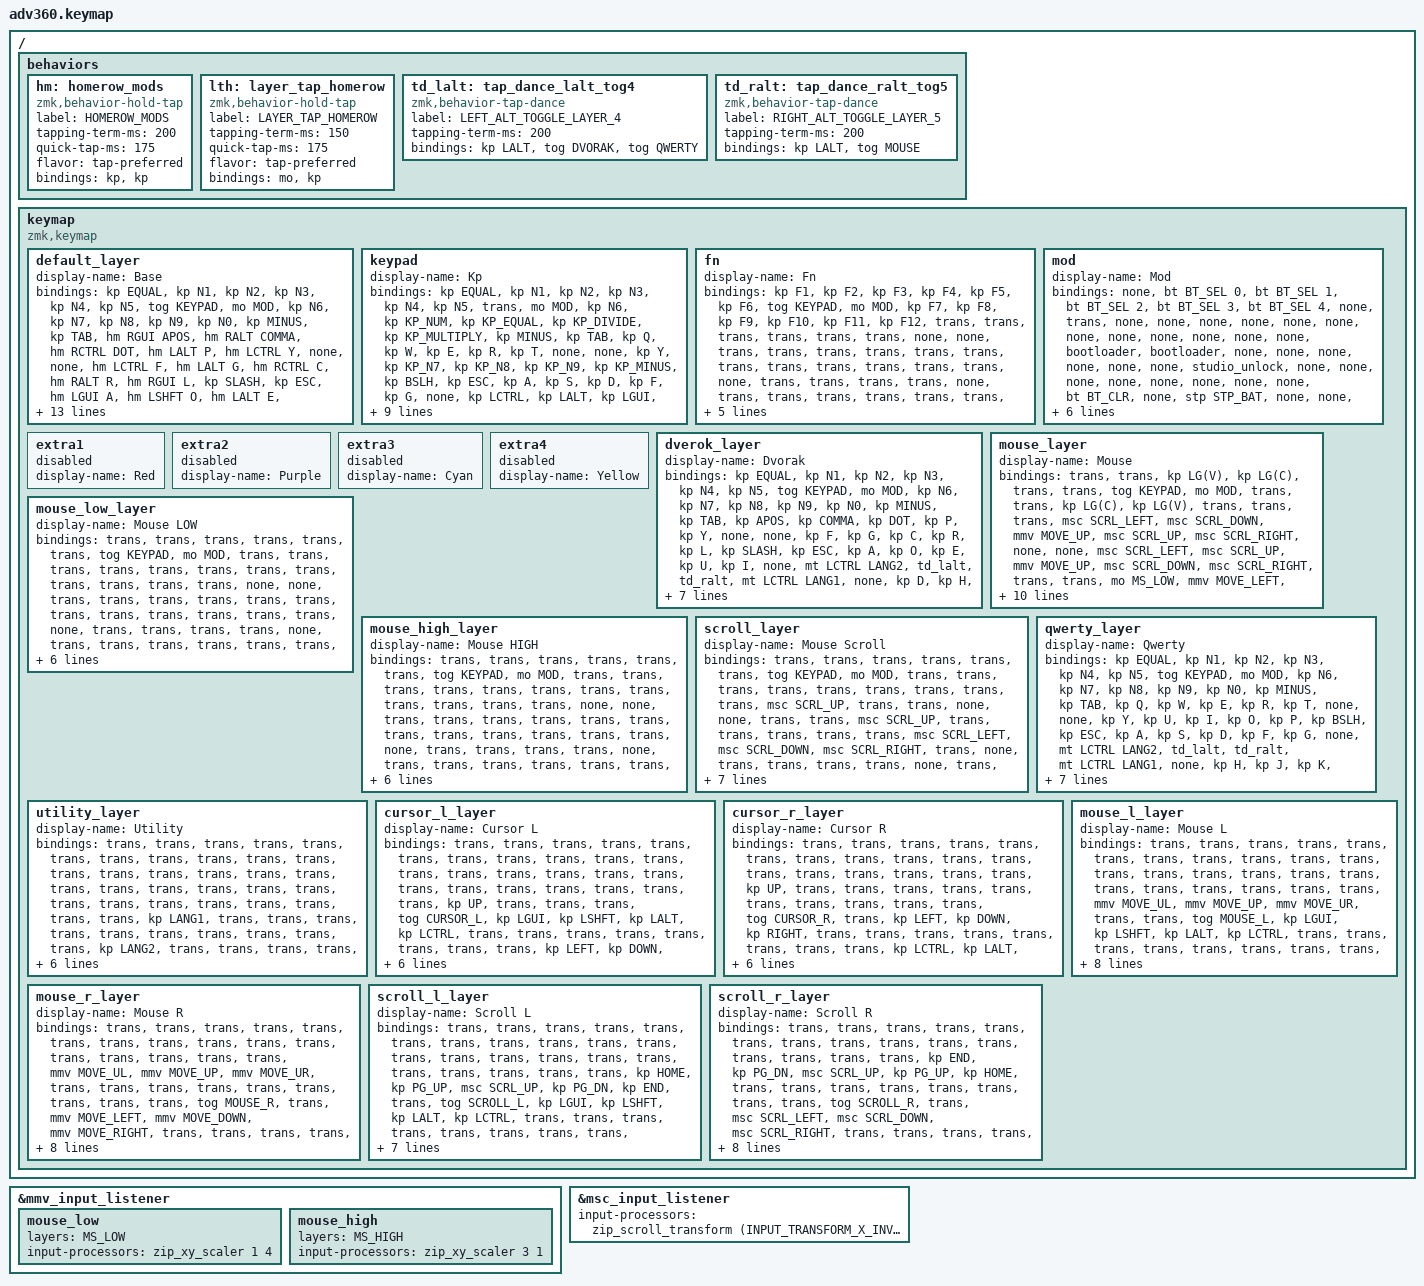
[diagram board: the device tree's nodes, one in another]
#include <behaviors.dtsi>
#include <dt-bindings/zmk/keys.h>
#include <dt-bindings/zmk/bt.h>
#include <dt-bindings/zmk/rgb.h>
#include <dt-bindings/zmk/stp.h>
#include <dt-bindings/zmk/backlight.h>

#define ZMK_POINTING_DEFAULT_MOVE_VAL 600  /* 600 */
#define ZMK_POINTING_DEFAULT_SCRL_VAL 20   /*  10 */
#include <dt-bindings/zmk/pointing.h>
/* Diagonal mouse moves (X and Y are encoded in separate bits) */
#define MOVE_UL (MOVE_UP | MOVE_LEFT)
#define MOVE_UR (MOVE_UP | MOVE_RIGHT)
#define MOVE_DL (MOVE_DOWN | MOVE_LEFT)
#define MOVE_DR (MOVE_DOWN | MOVE_RIGHT)
#include <input/processors.dtsi>
#include <dt-bindings/zmk/input_transform.h>

/* Layer indices (keep in sync with the order of layers in keymap) */
#define BASE    0
#define KEYPAD  1
#define FN      2
#define MOD     3
#define DVORAK  4
#define MOUSE   5
#define MS_LOW  6
#define MS_HIGH 7
#define SCROLL  8
#define QWERTY  9
#define UTIL    10
#define CURSOR_L 11
#define CURSOR_R 12
#define MOUSE_L 13
#define MOUSE_R 14
#define SCROLL_L 15
#define SCROLL_R 16

/ {
    behaviors {
      #include "macros.dtsi"
      #include "version.dtsi"

      hm: homerow_mods {
          compatible = "zmk,behavior-hold-tap";
          label = "HOMEROW_MODS";
          #binding-cells = <2>;
          tapping-term-ms = <200>;
          quick-tap-ms = <175>;
          flavor = "tap-preferred";
          bindings = <&kp>, <&kp>;
      };

      /* Layer-tap on home row keys (same feel as &hm, ported from kanata $lt).
       * tapping-term is shorter than &hm: with 200ms, a quick D(hold)-e(tap)
       * is not decided in time and types "de".
       * Usage: &lth LAYER KEY */
      lth: layer_tap_homerow {
          compatible = "zmk,behavior-hold-tap";
          label = "LAYER_TAP_HOMEROW";
          #binding-cells = <2>;
          tapping-term-ms = <150>;
          quick-tap-ms = <175>;
          flavor = "tap-preferred";
          bindings = <&mo>, <&kp>;
      };

      /* Thumb Ctrl keys use plain &mt (hold-preferred): hold = LCTRL,
       * tap = LANG2 (Eisu) / LANG1 (Kana).
       * Do not combine hold-tap and tap-dance on the same key:
       * - hold-tap inside tap-dance: the hold-tap listener runs before the
       *   tap-dance listener, so a key that interrupts the tap-dance is missed.
       * - tap-dance inside hold-tap: the tap-dance only sees the press when
       *   the key is released, so double taps hardly register. */

      td_lalt: tap_dance_lalt_tog4 {
          compatible = "zmk,behavior-tap-dance";
          label = "LEFT_ALT_TOGGLE_LAYER_4";
          #binding-cells = <0>;
          tapping-term-ms = <200>;
          bindings = <&kp LALT>, <&tog DVORAK>, <&tog QWERTY>;
      };

      td_ralt: tap_dance_ralt_tog5 {
          compatible = "zmk,behavior-tap-dance";
          label = "RIGHT_ALT_TOGGLE_LAYER_5";
          #binding-cells = <0>;
          tapping-term-ms = <200>;
          bindings = <&kp LALT>, <&tog MOUSE>;
      };
    };

  keymap {
    compatible = "zmk,keymap";

    /* layer 0 */
    default_layer {
      display-name = "Base";
      bindings = <
        &kp EQUAL &kp N1    &kp N2   &kp N3   &kp N4     &kp N5 &tog KEYPAD                                                    &mo MOD &kp N6  &kp N7    &kp N8       &kp N9        &kp N0          &kp MINUS
        &kp TAB   &hm RGUI APOS &hm RALT COMMA &hm RCTRL DOT &hm LALT P &hm LCTRL Y &none                                        &none &hm LCTRL F &hm LALT G &hm RCTRL C &hm RALT R &hm RGUI L     &kp SLASH
        &kp ESC   &hm LGUI A &hm LSHFT O &hm LALT E &hm LCTRL U &lth UTIL I &none &mt LCTRL LANG2 &td_lalt &td_ralt &mt LCTRL LANG1 &none &lth UTIL D &hm LCTRL H &hm LALT T &hm LSHFT N   &hm LGUI S      &kp BSLH
        &kp LSHFT &lth CURSOR_L SEMI  &lth SCROLL_L Q    &lth MOUSE_L J    &kp K      &kp X    &mt LGUI HOME &mt LGUI PG_UP            &kp B   &kp M     &lth MOUSE_R W &lth SCROLL_R V &lth CURSOR_R Z &kp RSHFT
        &mo FN    &kp GRAVE &kp CAPS &kp LEFT &kp RIGHT                &kp BSPC &kp DEL   &kp END  &kp PG_DN &kp ENTER &kp SPACE               &kp UP    &kp DOWN     &kp LBKT      &kp RBKT        &mo FN
      >;
    };
    /* layer 1 */
    keypad {
      display-name = "Kp";
      bindings = <
        &kp EQUAL &kp N1    &kp N2   &kp N3   &kp N4     &kp N5 &trans                                                         &mo MOD &kp N6 &kp KP_NUM &kp KP_EQUAL &kp KP_DIVIDE &kp KP_MULTIPLY &kp MINUS
        &kp TAB   &kp Q     &kp W    &kp E    &kp R      &kp T  &none                                                            &none &kp Y  &kp KP_N7  &kp KP_N8    &kp KP_N9     &kp KP_MINUS    &kp BSLH
        &kp ESC   &kp A     &kp S    &kp D    &kp F      &kp G  &none           &kp LCTRL &kp LALT &kp LGUI  &kp RCTRL           &none &kp H  &kp KP_N4  &kp KP_N5    &kp KP_N6     &kp KP_PLUS     &kp SQT
        &kp LSHFT &kp Z     &kp X    &kp C    &kp V      &kp B                            &kp HOME &kp PG_UP                           &kp N  &kp KP_N1  &kp KP_N2    &kp KP_N3     &kp KP_ENTER    &kp RSHFT
        &mo FN    &kp GRAVE &kp CAPS &kp LEFT &kp RIGHT                &kp BSPC &kp DEL   &kp END  &kp PG_DN &kp ENTER &kp KP_N0              &kp UP     &kp DOWN     &kp KP_DOT    &kp RBKT        &mo FN
      >;
    };
    /* layer 2 */
    fn {
      display-name = "Fn";
      bindings = <
        &kp F1 &kp F2 &kp F3 &kp F4 &kp F5 &kp F6  &tog KEYPAD                                   &mo MOD &kp F7 &kp F8 &kp F9 &kp F10 &kp F11 &kp F12
        &trans &trans &trans &trans &trans &trans  &none                                           &none &trans &trans &trans &trans  &trans  &trans
        &trans &trans &trans &trans &trans &trans  &none        &trans &trans &trans &trans        &none &trans &trans &trans &trans  &trans  &trans
        &trans &trans &trans &trans &trans &trans                      &trans &trans                     &trans &trans &trans &trans  &trans  &trans
        &trans &trans &trans &trans &trans               &trans &trans &trans &trans &trans &trans              &trans &trans &trans  &trans  &trans
      >;
    };
    /* layer 3 */
    mod {
      display-name = "Mod";
      bindings = <
        &none &bt BT_SEL 0 &bt BT_SEL 1 &bt BT_SEL 2 &bt BT_SEL 3 &bt BT_SEL 4 &none                                                                     &trans                 &none        &none        &none        &none &none &none
        &none &none        &none        &none        &none        &none        &bootloader                                                               &bootloader            &none        &none        &none        &none &none &none
        &studio_unlock &none &none      &none        &none        &none        &none                   &none &none &bt BT_CLR &none                      &stp STP_BAT           &none        &none        &none        &none &none &none
        &none &none        &none        &none        &macro_ver   &none                                      &none &none                                                        &none        &none        &none        &none &none &none
        &none &none        &none        &none        &none                                       &none &none &none &none      &bl BL_TOG &rgb_ug RGB_TOG                                     &bl BL_INC   &bl BL_DEC   &none &none &none
      >;
    };
    extra1 { 
      display-name = "Red";    
      status = "reserved";
    };

    extra2 { 
      display-name = "Purple";    
      status = "reserved";
    };

    extra3 { 
      display-name = "Cyan";    
      status = "reserved";
    };

    extra4 { 
      display-name = "Yellow";    
      status = "reserved";
    };
    /* layer 4 */
    dverok_layer {
      display-name = "Dvorak";
      bindings = <
        &kp EQUAL &kp N1    &kp N2    &kp N3    &kp N4    &kp N5    &tog KEYPAD                                                            &mo MOD &kp N6    &kp N7    &kp N8    &kp N9    &kp N0    &kp MINUS
        &kp TAB   &kp APOS  &kp COMMA &kp DOT   &kp P     &kp Y     &none                                                                    &none &kp F     &kp G     &kp C     &kp R     &kp L     &kp SLASH
        &kp ESC   &kp A     &kp O     &kp E     &kp U     &kp I     &none       &mt LCTRL LANG2     &td_lalt      &td_ralt  &mt LCTRL LANG1  &none &kp D     &kp H     &kp T     &kp N     &kp S     &kp BSLH
        &kp LSHFT &kp SEMI  &kp Q     &kp J     &kp K     &kp X                                     &mt LGUI HOME &mt LGUI PG_UP                   &kp B     &kp M     &kp W     &kp V     &kp Z     &kp RSHFT
        &mo FN    &kp GRAVE &kp CAPS  &kp LEFT  &kp RIGHT                       &kp BSPC  &kp DEL   &kp END       &kp PG_DN &kp ENTER &kp SPACE              &kp UP    &kp DOWN  &kp LBKT  &kp RBKT  &mo FN
      >;
    };
    /* layer 5 */
    mouse_layer {
      display-name = "Mouse";
      bindings = <
        &trans    &trans    &kp LG(V) &kp LG(C) &trans    &trans    &tog KEYPAD                                                            &mo MOD &trans    &trans    &kp LG(C) &kp LG(V)  &trans   &trans
        &trans    &msc SCRL_LEFT &msc SCRL_DOWN &mmv MOVE_UP &msc SCRL_UP &msc SCRL_RIGHT &none                                              &none &msc SCRL_LEFT &msc SCRL_UP &mmv MOVE_UP &msc SCRL_DOWN &msc SCRL_RIGHT &trans
        &trans    &mo MS_LOW &mmv MOVE_LEFT &mmv MOVE_DOWN &mmv MOVE_RIGHT &mo MS_HIGH &none &trans &trans        &trans &trans              &none &mo MS_HIGH &mmv MOVE_LEFT &mmv MOVE_DOWN &mmv MOVE_RIGHT &mo MS_LOW &trans
        &trans    &kp LGUI  &kp LSHFT &kp LALT  &kp LCTRL &trans                                    &trans        &trans                           &trans    &kp LCTRL &kp LALT  &kp LSHFT &kp LGUI  &trans
        &mo FN    &mo SCROLL &trans   &trans    &trans                          &mkp LCLK &mkp RCLK &trans        &trans &mkp RCLK &mkp LCLK                 &trans    &trans    &trans    &trans    &mo FN
      >;
    };
    /* layer 6 */
    mouse_low_layer {
      display-name = "Mouse LOW";
      bindings = <
        &trans    &trans    &trans    &trans    &trans    &trans    &tog KEYPAD                                                            &mo MOD &trans    &trans    &trans    &trans    &trans    &trans
        &trans    &trans    &trans    &trans    &trans    &trans    &none                                                                    &none &trans    &trans    &trans    &trans    &trans    &trans
        &trans    &trans    &trans    &trans    &trans    &trans    &none                 &trans    &trans        &trans &trans              &none &trans    &trans    &trans    &trans    &trans    &trans
        &trans    &trans    &trans    &trans    &trans    &trans                                    &trans        &trans                           &trans    &trans    &trans    &trans    &trans    &trans
        &mo FN    &mo SCROLL &trans   &trans    &trans                          &trans    &trans    &trans        &trans &trans    &trans                    &trans    &trans    &trans    &trans    &mo FN
      >;
    };
    /* layer 7 */
    mouse_high_layer {
      display-name = "Mouse HIGH";
      bindings = <
        &trans    &trans    &trans    &trans    &trans    &trans    &tog KEYPAD                                                            &mo MOD &trans    &trans    &trans    &trans    &trans    &trans
        &trans    &trans    &trans    &trans    &trans    &trans    &none                                                                    &none &trans    &trans    &trans    &trans    &trans    &trans
        &trans    &trans    &trans    &trans    &trans    &trans    &none                 &trans    &trans        &trans &trans              &none &trans    &trans    &trans    &trans    &trans    &trans
        &trans    &trans    &trans    &trans    &trans    &trans                                    &trans        &trans                           &trans    &trans    &trans    &trans    &trans    &trans
        &mo FN    &mo SCROLL &trans   &trans    &trans                          &trans    &trans    &trans        &trans &trans    &trans                    &trans    &trans    &trans    &trans    &mo FN
      >;
    };
    /* layer 8 */
    scroll_layer {
      display-name = "Mouse Scroll";
      bindings = <
        &trans    &trans    &trans    &trans    &trans    &trans    &tog KEYPAD                                                            &mo MOD &trans    &trans    &trans    &trans    &trans    &trans
        &trans    &trans    &trans    &msc SCRL_UP &trans &trans    &none                                                                    &none &trans    &trans    &msc SCRL_UP &trans &trans  &trans
        &trans    &trans    &msc SCRL_LEFT &msc SCRL_DOWN &msc SCRL_RIGHT &trans &none    &trans    &trans        &trans &trans              &none &trans    &msc SCRL_LEFT &msc SCRL_DOWN &msc SCRL_RIGHT &trans &trans
        &trans    &trans    &trans    &trans    &trans    &trans                                    &trans        &trans                           &trans    &trans    &trans    &trans    &trans    &trans
        &mo FN    &mo SCROLL &trans   &trans    &trans                          &trans    &trans    &trans        &trans &trans    &trans                    &trans    &trans    &trans    &trans    &mo FN
      >;
    };
    /* layer 9 */
    qwerty_layer {
      display-name = "Qwerty";
      bindings = <
        &kp EQUAL &kp N1    &kp N2   &kp N3   &kp N4     &kp N5 &tog KEYPAD                                                    &mo MOD &kp N6 &kp N7 &kp N8    &kp N9   &kp N0   &kp MINUS
        &kp TAB   &kp Q     &kp W    &kp E    &kp R      &kp T  &none                                                            &none &kp Y  &kp U  &kp I     &kp O    &kp P    &kp BSLH
        &kp ESC   &kp A     &kp S    &kp D    &kp F      &kp G  &none   &mt LCTRL LANG2   &td_lalt &td_ralt  &mt LCTRL LANG1     &none &kp H  &kp J  &kp K     &kp L    &kp SEMI &kp APOS
        &kp LSHFT &kp Z     &kp X    &kp C    &kp V      &kp B                       &mt LGUI HOME &mt LGUI PG_UP                      &kp N  &kp M  &kp COMMA &kp DOT  &kp SLASH &kp RSHFT
        &mo FN    &kp GRAVE &kp CAPS &kp LEFT &kp RIGHT                &kp BSPC &kp DEL   &kp END  &kp PG_DN &kp ENTER &kp SPACE              &kp UP &kp DOWN  &kp LBKT &kp RBKT &mo FN
      >;
    };
    /* layer 10 */
    /* hold Dvorak i / d, then e -> Kana, t -> Eisu */
    utility_layer {
      display-name = "Utility";
      bindings = <
        &trans          &trans          &trans          &trans          &trans          &trans          &trans                                                                          &trans          &trans          &trans          &trans          &trans          &trans          &trans
        &trans          &trans          &trans          &trans          &trans          &trans          &trans                                                                          &trans          &trans          &trans          &trans          &trans          &trans          &trans
        &trans          &trans          &trans          &kp LANG1       &trans          &trans          &trans                      &trans    &trans    &trans    &trans                &trans          &trans          &trans          &kp LANG2       &trans          &trans          &trans
        &trans          &tog CURSOR_R   &tog SCROLL_R   &tog MOUSE_R    &trans          &trans                                                &trans    &trans                                          &trans          &trans          &tog MOUSE_L    &tog SCROLL_L   &tog CURSOR_L   &trans
        &trans          &trans          &trans          &trans          &trans                                            &trans    &trans    &trans    &trans    &trans    &trans                                      &trans          &trans          &trans          &trans          &trans
      >;
    };
    /* layer 11 */
    /* hold Dvorak ;, left a o e u = mods, right c / h t n = arrows */
    cursor_l_layer {
      display-name = "Cursor L";
      bindings = <
        &trans          &trans          &trans          &trans          &trans          &trans          &trans                                                                          &trans          &trans          &trans          &trans          &trans          &trans          &trans
        &trans          &trans          &trans          &trans          &trans          &trans          &trans                                                                          &trans          &trans          &trans          &kp UP          &trans          &trans          &trans
        &tog CURSOR_L   &kp LGUI        &kp LSHFT       &kp LALT        &kp LCTRL       &trans          &trans                      &trans    &trans    &trans    &trans                &trans          &trans          &kp LEFT        &kp DOWN        &kp RIGHT       &trans          &trans
        &trans          &tog CURSOR_L   &trans          &trans          &trans          &trans                                                &trans    &trans                                          &trans          &trans          &trans          &trans          &trans          &trans
        &trans          &trans          &trans          &trans          &trans                                            &trans    &trans    &trans    &trans    &trans    &trans                                      &trans          &trans          &trans          &trans          &trans
      >;
    };
    /* layer 12 */
    /* hold Dvorak z, right h t n s = mods, left . / o e u = arrows */
    cursor_r_layer {
      display-name = "Cursor R";
      bindings = <
        &trans          &trans          &trans          &trans          &trans          &trans          &trans                                                                          &trans          &trans          &trans          &trans          &trans          &trans          &trans
        &trans          &trans          &trans          &kp UP          &trans          &trans          &trans                                                                          &trans          &trans          &trans          &trans          &trans          &trans          &trans
        &tog CURSOR_R   &trans          &kp LEFT        &kp DOWN        &kp RIGHT       &trans          &trans                      &trans    &trans    &trans    &trans                &trans          &trans          &kp LCTRL       &kp LALT        &kp LSHFT       &kp LGUI        &trans
        &trans          &trans          &trans          &trans          &trans          &trans                                                &trans    &trans                                          &trans          &trans          &trans          &trans          &tog CURSOR_R   &trans
        &trans          &trans          &trans          &trans          &trans                                            &trans    &trans    &trans    &trans    &trans    &trans                                      &trans          &trans          &trans          &trans          &trans
      >;
    };
    /* layer 13 */
    /* hold Dvorak j, left a o e u = mods, q / k = slow / fast,
     * right c / h t n = move, g r / m v = diagonal, thumbs = clicks */
    mouse_l_layer {
      display-name = "Mouse L";
      bindings = <
        &trans          &trans          &trans          &trans          &trans          &trans          &trans                                                                          &trans          &trans          &trans          &trans          &trans          &trans          &trans
        &trans          &trans          &trans          &trans          &trans          &trans          &trans                                                                          &trans          &trans          &mmv MOVE_UL    &mmv MOVE_UP    &mmv MOVE_UR    &trans          &trans
        &tog MOUSE_L    &kp LGUI        &kp LSHFT       &kp LALT        &kp LCTRL       &trans          &trans                      &trans    &trans    &trans    &trans                &trans          &trans          &mmv MOVE_LEFT  &mmv MOVE_DOWN  &mmv MOVE_RIGHT &trans          &trans
        &trans          &trans          &mo MS_LOW      &tog MOUSE_L    &mo MS_HIGH     &trans                                                &trans    &trans                                          &trans          &mmv MOVE_DL    &trans          &mmv MOVE_DR    &trans          &trans
        &trans          &trans          &trans          &trans          &trans                                            &mkp LCLK &mkp RCLK &trans    &trans    &mkp RCLK &mkp LCLK                                   &trans          &trans          &trans          &trans          &trans
      >;
    };
    /* layer 14 */
    /* hold Dvorak w, right h t n s = mods, v / m = slow / fast,
     * left . / o e u = move, , p / q k = diagonal, thumbs = clicks */
    mouse_r_layer {
      display-name = "Mouse R";
      bindings = <
        &trans          &trans          &trans          &trans          &trans          &trans          &trans                                                                          &trans          &trans          &trans          &trans          &trans          &trans          &trans
        &trans          &trans          &mmv MOVE_UL    &mmv MOVE_UP    &mmv MOVE_UR    &trans          &trans                                                                          &trans          &trans          &trans          &trans          &trans          &trans          &trans
        &tog MOUSE_R    &trans          &mmv MOVE_LEFT  &mmv MOVE_DOWN  &mmv MOVE_RIGHT &trans          &trans                      &trans    &trans    &trans    &trans                &trans          &trans          &kp LCTRL       &kp LALT        &kp LSHFT       &kp LGUI        &trans
        &trans          &trans          &mmv MOVE_DL    &trans          &mmv MOVE_DR    &trans                                                &trans    &trans                                          &trans          &mo MS_HIGH     &tog MOUSE_R    &mo MS_LOW      &trans          &trans
        &trans          &trans          &trans          &trans          &trans                                            &mkp LCLK &mkp RCLK &trans    &trans    &mkp RCLK &mkp LCLK                                   &trans          &trans          &trans          &trans          &trans
      >;
    };
    /* layer 15 */
    /* hold Dvorak q, left a o e u = mods, right c / h t n = scroll,
     * f g c r l = home pgup up pgdn end, thumbs = clicks */
    scroll_l_layer {
      display-name = "Scroll L";
      bindings = <
        &trans          &trans          &trans          &trans          &trans          &trans          &trans                                                                          &trans          &trans          &trans          &trans          &trans          &trans          &trans
        &trans          &trans          &trans          &trans          &trans          &trans          &trans                                                                          &trans          &kp HOME        &kp PG_UP       &msc SCRL_UP    &kp PG_DN       &kp END         &trans
        &tog SCROLL_L   &kp LGUI        &kp LSHFT       &kp LALT        &kp LCTRL       &trans          &trans                      &trans    &trans    &trans    &trans                &trans          &trans          &msc SCRL_LEFT  &msc SCRL_DOWN  &msc SCRL_RIGHT &trans          &trans
        &trans          &trans          &tog SCROLL_L   &trans          &trans          &trans                                                &trans    &trans                                          &trans          &trans          &trans          &trans          &trans          &trans
        &trans          &trans          &trans          &trans          &trans                                            &mkp LCLK &mkp RCLK &trans    &trans    &mkp RCLK &mkp LCLK                                   &trans          &trans          &trans          &trans          &trans
      >;
    };
    /* layer 16 */
    /* hold Dvorak v, right h t n s = mods, left . / o e u = scroll,
     * ' , . p y = end pgdn up pgup home, thumbs = clicks */
    scroll_r_layer {
      display-name = "Scroll R";
      bindings = <
        &trans          &trans          &trans          &trans          &trans          &trans          &trans                                                                          &trans          &trans          &trans          &trans          &trans          &trans          &trans
        &trans          &kp END         &kp PG_DN       &msc SCRL_UP    &kp PG_UP       &kp HOME        &trans                                                                          &trans          &trans          &trans          &trans          &trans          &trans          &trans
        &tog SCROLL_R   &trans          &msc SCRL_LEFT  &msc SCRL_DOWN  &msc SCRL_RIGHT &trans          &trans                      &trans    &trans    &trans    &trans                &trans          &trans          &kp LCTRL       &kp LALT        &kp LSHFT       &kp LGUI        &trans
        &trans          &trans          &trans          &trans          &trans          &trans                                                &trans    &trans                                          &trans          &trans          &trans          &tog SCROLL_R   &trans          &trans
        &trans          &trans          &trans          &trans          &trans                                            &mkp LCLK &mkp RCLK &trans    &trans    &mkp RCLK &mkp LCLK                                   &trans          &trans          &trans          &trans          &trans
      >;
    };
  };
};

&mmv_input_listener {
  mouse_low {
    layers = <MS_LOW>;
    input-processors = <&zip_xy_scaler 1 4>;
  };

  mouse_high {
    layers = <MS_HIGH>;
    input-processors = <&zip_xy_scaler 3 1>;
  };
};

&msc_input_listener {
  input-processors = <&zip_scroll_transform (INPUT_TRANSFORM_X_INVERT | INPUT_TRANSFORM_Y_INVERT)>;
};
